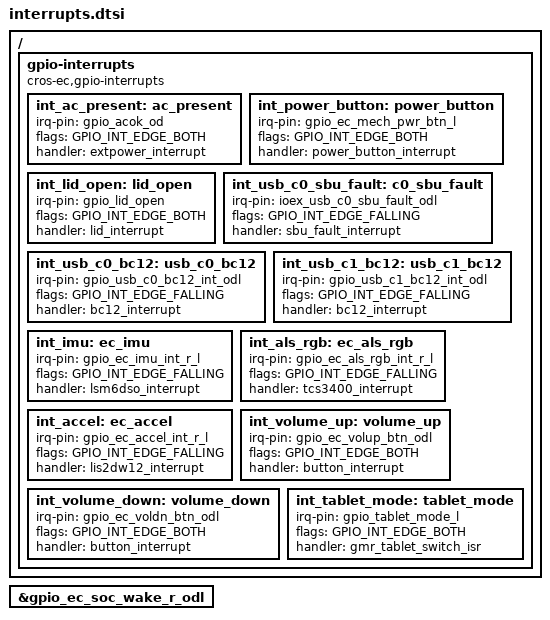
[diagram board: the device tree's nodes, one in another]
/* Copyright 2022 The ChromiumOS Authors
 * Use of this source code is governed by a BSD-style license that can be
 * found in the LICENSE file.
 */

/ {
	gpio-interrupts {
		compatible = "cros-ec,gpio-interrupts";

		int_ac_present: ac_present {
			irq-pin = <&gpio_acok_od>;
			flags = <GPIO_INT_EDGE_BOTH>;
			handler = "extpower_interrupt";
		};
		int_power_button: power_button {
			irq-pin = <&gpio_ec_mech_pwr_btn_l>;
			flags = <GPIO_INT_EDGE_BOTH>;
			handler = "power_button_interrupt";
		};
		int_lid_open: lid_open {
			irq-pin = <&gpio_lid_open>;
			flags = <GPIO_INT_EDGE_BOTH>;
			handler = "lid_interrupt";
		};
		int_usb_c0_sbu_fault: c0_sbu_fault {
			irq-pin = <&ioex_usb_c0_sbu_fault_odl>;
			flags = <GPIO_INT_EDGE_FALLING>;
			handler = "sbu_fault_interrupt";
		};
		int_usb_c0_bc12: usb_c0_bc12 {
			irq-pin = <&gpio_usb_c0_bc12_int_odl>;
			flags = <GPIO_INT_EDGE_FALLING>;
			handler = "bc12_interrupt";
		};
		int_usb_c1_bc12: usb_c1_bc12 {
			irq-pin = <&gpio_usb_c1_bc12_int_odl>;
			flags = <GPIO_INT_EDGE_FALLING>;
			handler = "bc12_interrupt";
		};
		int_imu: ec_imu {
			irq-pin = <&gpio_ec_imu_int_r_l>;
			flags = <GPIO_INT_EDGE_FALLING>;
			handler = "lsm6dso_interrupt";
		};
		int_als_rgb: ec_als_rgb {
			irq-pin = <&gpio_ec_als_rgb_int_r_l>;
			flags = <GPIO_INT_EDGE_FALLING>;
			handler = "tcs3400_interrupt";
		};
		int_accel: ec_accel {
			irq-pin = <&gpio_ec_accel_int_r_l>;
			flags = <GPIO_INT_EDGE_FALLING>;
			handler = "lis2dw12_interrupt";
		};
		int_volume_up: volume_up {
			irq-pin = <&gpio_ec_volup_btn_odl>;
			flags = <GPIO_INT_EDGE_BOTH>;
			handler = "button_interrupt";
		};
		int_volume_down: volume_down {
			irq-pin = <&gpio_ec_voldn_btn_odl>;
			flags = <GPIO_INT_EDGE_BOTH>;
			handler = "button_interrupt";
		};
		int_tablet_mode: tablet_mode {
			irq-pin = <&gpio_tablet_mode_l>;
			flags = <GPIO_INT_EDGE_BOTH>;
			handler = "gmr_tablet_switch_isr";
		};
	};
};

/* Required node label that doesn't is named differently on Rex */
gpio_ec_pch_wake_odl: &gpio_ec_soc_wake_r_odl {};
